AUTOSAR XML (schema 4-3-0)
package /App_SeatHeating
  client server interface If_Setting
    operation Write
      arg HeatDial: type=uint16, direction=IN, server-argument-impl-policy=USE-ARGUMENT-TYPE
  client server interface If_Heating
    operation Write
      arg HeatValue: type=uint16, direction=IN, server-argument-impl-policy=USE-ARGUMENT-TYPE
  sender receiver interface If_DialLed
    data On: sw-impl-policy=QUEUED, type=boolean
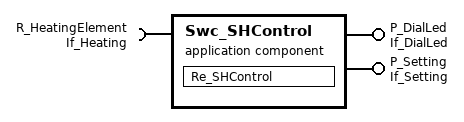
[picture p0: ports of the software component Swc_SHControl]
  application sw component type Swc_SHControl
    provide port P_DialLed: queued-sender-com-spec=On, provided-interface=If_DialLed
    provide port P_Setting: server-com-spec{operation=If_Setting/Write, queue-length=1}, provided-interface=If_Setting
    require port R_HeatingElement: client-com-spec=If_Heating/Write, required-interface=If_Heating
    behavior InternalBehavior
      operation invoked event OIE_Re_SHControl_P_Setting_Write: start-on-event=Re_SHControl, operation=P_Setting.Write
      runnable Re_SHControl
        data-send-points:
          access DSP_Re_SHControl_P_DialLed_On: accessed-variable=P_DialLed.On, scope=COMMUNICATION-INTER-ECU
        sync call SSCP_Re_SHControl_R_HeatingElement_Write: operation=R_HeatingElement.Write
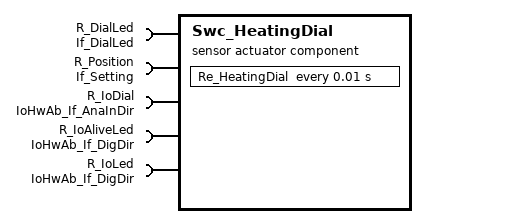
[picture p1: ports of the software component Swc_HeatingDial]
  sensor actuator sw component type Swc_HeatingDial
    5 x require port:
      R_DialLed: queued-receiver-com-spec{data-element=On, queue-length=4}, required-interface=If_DialLed
      R_Position: client-com-spec=If_Setting/Write, required-interface=If_Setting
      R_IoDial: client-com-spec=ReadDirect, required-interface=IoHwAb_If_AnaInDir
      R_IoAliveLed: client-com-spec=WriteDirect, required-interface=IoHwAb_If_DigDir
      R_IoLed: client-com-spec=WriteDirect, required-interface=IoHwAb_If_DigDir
    behavior InternalBehavior
      timing event TE_Re_HeatingDial: start-on-event=Re_HeatingDial, period=0.01
      runnable Re_HeatingDial
        data-receive-point-by-arguments:
          access DRPBA_Re_HeatingDial_R_DialLed_On: accessed-variable=R_DialLed.On, scope=COMMUNICATION-INTER-ECU
        4 x sync call:
          SSCP_Re_HeatingDial_R_IoAliveLed_WriteDirect: operation=R_IoAliveLed.WriteDirect
          SSCP_Re_HeatingDial_R_IoDial_ReadDirect: operation=R_IoDial.ReadDirect
          SSCP_Re_HeatingDial_R_IoLed_WriteDirect: operation=R_IoLed.WriteDirect
          SSCP_Re_HeatingDial_R_Position_Write: operation=R_Position.Write
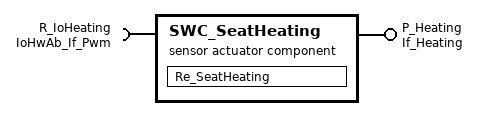
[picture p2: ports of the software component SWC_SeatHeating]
  sensor actuator sw component type SWC_SeatHeating
    provide port P_Heating: server-com-spec{operation=If_Heating/Write, queue-length=1}, provided-interface=If_Heating
    require port R_IoHeating: required-com-specs=[SetDutyCycle, SetOutputToIdle], required-interface=IoHwAb_If_Pwm
    behavior InternalBehavior
      operation invoked event OIE_Re_SeatHeating_P_Heating_Write: start-on-event=Re_SeatHeating, operation=P_Heating.Write
      runnable Re_SeatHeating
        sync call SSCP_Re_SeatHeating_R_IoHeating_SetDutyCycle: operation=R_IoHeating.SetDutyCycle
        sync call SSCP_Re_SeatHeating_R_IoHeating_SetOutputToIdle: operation=R_IoHeating.SetOutputToIdle
